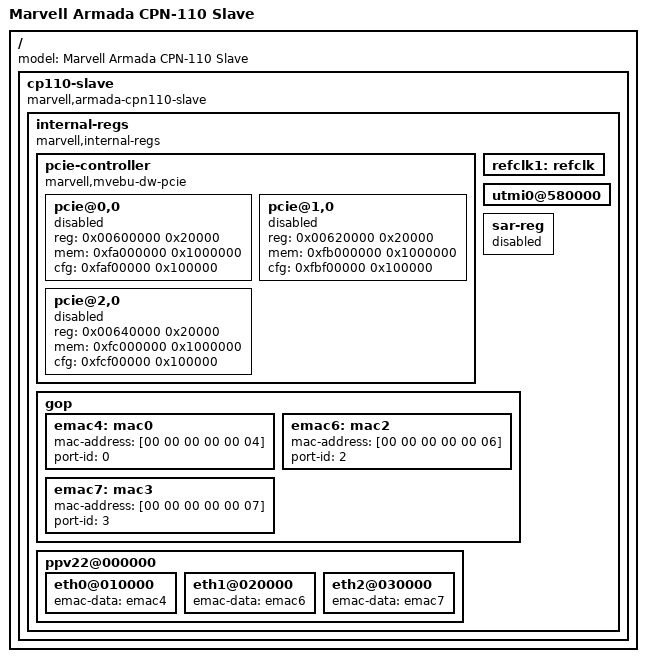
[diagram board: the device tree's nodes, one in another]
/*
 * ***************************************************************************
 * Copyright (C) 2015 Marvell International Ltd.
 * ***************************************************************************
 * This program is free software: you can redistribute it and/or modify it
 * under the terms of the GNU General Public License as published by the Free
 * Software Foundation, either version 2 of the License, or any later version.
 *
 * This program is distributed in the hope that it will be useful,
 * but WITHOUT ANY WARRANTY; without even the implied warranty of
 * MERCHANTABILITY or FITNESS FOR A PARTICULAR PURPOSE.  See the
 * GNU General Public License for more details.
 *
 * You should have received a copy of the GNU General Public License
 * along with this program.  If not, see <http://www.gnu.org/licenses/>.
 * ***************************************************************************
 */

/ {
	model = "Marvell Armada CPN-110 Slave";

	cp110-slave {
		compatible = "marvell,armada-cpn110-slave", "simple-bus";
		#address-cells = <1>;
		#size-cells = <1>;

		internal-regs {
			compatible = "marvell,internal-regs", "simple-bus";
			ranges = <0x0000 0xf4000000 0x1000000>;
			#address-cells = <1>;
			#size-cells = <1>;

			#include "cp110.dtsi"

			pcie-controller {
				#address-cells = <1>;
				#size-cells = <1>;
				compatible = "marvell,mvebu-dw-pcie";

				pcie@0,0 {
					reg = <0x00600000 0x20000>;
					mem = <0xfa000000 0x1000000>;
					cfg = <0xfaf00000 0x100000>;
					status = "disabled";
				};
				pcie@1,0 {
					reg = <0x00620000 0x20000>;
					mem = <0xfb000000 0x1000000>;
					cfg = <0xfbf00000 0x100000>;
					status = "disabled";
				};
				pcie@2,0 {
					reg = <0x00640000 0x20000>;
					mem = <0xfc000000 0x1000000>;
					cfg = <0xfcf00000 0x100000>;
					status = "disabled";
				};
			};
		};
	};

	cp110-slave {
		internal-regs {
			refclk1: refclk {
			};
			utmi0@580000 {
				status = "okay";
			};
			sar-reg {
				status = "disabled";
			};
			gop {
				emac4: mac0 {
					mac-address = [00 00 00 00 00 04];
					port-id = <0>; /* gop_port_id */
				};
				emac6: mac2 {
					mac-address = [00 00 00 00 00 06];
					port-id = <2>; /* gop_port_id */
				};
				emac7: mac3 {
					mac-address = [00 00 00 00 00 07];
					port-id = <3>; /* gop_port_id */
				};
			};
			ppv22@000000 {
				eth0@010000 {
					emac-data = <&emac4>;
				};
				eth1@020000 {
					emac-data = <&emac6>;
				};
				eth2@030000 {
					emac-data = <&emac7>;
				};
			};
		};
	};
};
